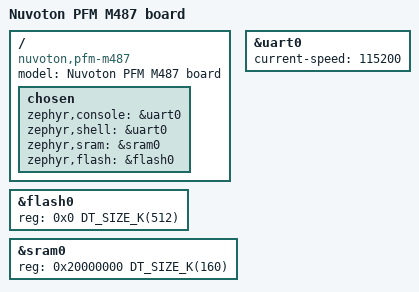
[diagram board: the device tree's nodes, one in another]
/*
 * Copyright (c) 2020 Linumiz
 *
 * SPDX-License-Identifier: Apache-2.0
 */

/dts-v1/;
#include <nuvoton/m48x.dtsi>

/ {
	model = "Nuvoton PFM M487 board";
	compatible = "nuvoton,pfm-m487", "nuvoton,m487";

	chosen {
		zephyr,console = &uart0;
		zephyr,shell = &uart0;
		zephyr,sram = &sram0;
		zephyr,flash = &flash0;
	};
};

&flash0 {
	reg = <0x0 DT_SIZE_K(512)>;
};

&sram0 {
	reg = <0x20000000 DT_SIZE_K(160)>;
};

&uart0 {
	current-speed = <115200>;
	status = "okay";
};
